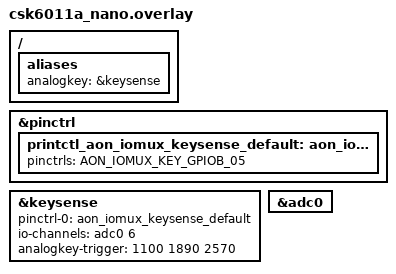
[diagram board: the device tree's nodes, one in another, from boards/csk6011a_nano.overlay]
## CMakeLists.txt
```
# SPDX-License-Identifier: Apache-2.0

cmake_minimum_required(VERSION 3.20.0)

set(SUPPORT_BOARDS csk6012_nano csk6011a_nano)
if(NOT ${BOARD} IN_LIST SUPPORT_BOARDS)
    message("Please choose one of the following boards:")
    foreach(item ${SUPPORT_BOARDS})
        message(STATUS ${item})
    endforeach()
    message(FATAL_ERROR "\nThe project does not support the ${BOARD}")
endif()

find_package(Zephyr HINTS $ENV{ZEPHYR_BASE})
project(KEYSENSE)

target_sources(app PRIVATE src/main.c)
```

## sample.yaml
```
tests:
  sample.board.csk6.driver.keysense:
    platform_allow: csk6011a_nano
    tags: csk6
    timeout: 10
    harness: console
    harness_config:
      type: one_line
      regex:
        - "csk6 keysense sample application start"
```

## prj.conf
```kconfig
CONFIG_ADC=y
CONFIG_LOG=y
CONFIG_LOG_MODE_MINIMAL=y
CONFIG_KSCAN_CSK6=y
CONFIG_KSCAN=y
CONFIG_PRINTK_SYNC=y
```

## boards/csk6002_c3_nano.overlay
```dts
/*
 * SPDX-License-Identifier: Apache-2.0
 *
 * Copyright (c) 2021 STMicroelectronics
 */

&keysense {
    status = "okay";

	//keysense use adc channel 6 to sample
    io-channels = <&adc0 6>;

    //Trigger voltage of each analog key (mV)
    analogkey-trigger = <1100 1890 2570>;
};


/ {
     aliases {
        analogkey = &keysense;
     };
};

&adc0 {
        status = "okay";
};
```

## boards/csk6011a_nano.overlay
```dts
/*
 * Copyright (c) 2023 Anhui(Shenzhen) Listenai Co., Ltd.
 *
 * SPDX-License-Identifier: Apache-2.0
 */

 &pinctrl {
	/* ADC alternate function */
	printctl_aon_iomux_keysense_default: aon_iomux_keysense_default {
		pinctrls = <AON_IOMUX_KEY_GPIOB_05>;
	};
};

&keysense {
	status = "okay";
	pinctrl-0 = <&aon_iomux_keysense_default>;
	pinctrl-names = "default";

	//keysense use adc channel 6 to sample
	io-channels = <&adc0 6>;

	//Trigger voltage of each analog key (mV)
	analogkey-trigger = <1100 1890 2570>;
};


/ {
	aliases {
		analogkey = &keysense;
	};
};

&adc0 {
	status = "okay";
};
```

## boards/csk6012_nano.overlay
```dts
/*
 * Copyright (c) 2023 Anhui(Shenzhen) Listenai Co., Ltd.
 *
 * SPDX-License-Identifier: Apache-2.0
 */

&keysense {
	status = "okay";

	//keysense use adc channel 6 to sample
	io-channels = <&adc0 6>;

	//Trigger voltage of each analog key (mV)
	analogkey-trigger = <1100 1890 2570>;
};


/ {
	aliases {
		analogkey = &keysense;
	};
};

&adc0 {
	status = "okay";
};
```

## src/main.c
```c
/*
 * Copyright (c) 2023 Anhui(Shenzhen) Listenai Co., Ltd.
 *
 * SPDX-License-Identifier: Apache-2.0
 */

#include <drivers/gpio.h>
#include <drivers/kscan.h>
#include <soc.h>
#include <sys/printk.h>
#include <zephyr.h>

#define KSCAN_DEVICE DT_LABEL(DT_ALIAS(analogkey))

// #define KSCAN_NODE DT_INST(0, listenai_csk_keysense)

static void kb_callback(const struct device *dev, uint32_t row, uint32_t col, bool pressed)
{
	ARG_UNUSED(dev);

	printk("Key row = %d col = %d Pressed = %u\n", row, col, pressed);
}

void main(void)
{
	const struct device *kscan_dev = device_get_binding(KSCAN_DEVICE);
	int ret = 0;

	if (!device_is_ready(kscan_dev)) {
		printk("kscan device  not ready \n");
		return;
	}

	ret = kscan_config(kscan_dev, kb_callback);
	if (ret != 0) {
		printk("kscan config error \n");
		return;
	}

	printk("csk6 keysense sample application start\n");
}
```
